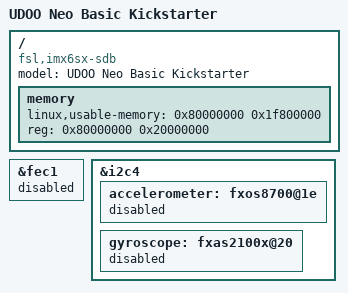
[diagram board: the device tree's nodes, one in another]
/*
 * Copyright (C) 2015 Jasbir Matharu
 * Author: Ettore Chimenti <ek5.chimenti@gmail.com>
 *
 * This program is free software; you can redistribute it and/or modify
 * it under the terms of the GNU General Public License version 2 as
 * published by the Free Software Foundation.
 */


/ {
	model = "UDOO Neo Basic Kickstarter";
	compatible = "fsl,imx6sx-sdb", "fsl,imx6sx";
	
	memory {
		linux,usable-memory = <0x80000000 0x1f800000>;
		reg = <0x80000000 0x20000000>;
	};
};

&fec1 {
	status = "disabled";
};

&i2c4 {
	accelerometer: fxos8700@1e {
		status = "disabled";
	};
	gyroscope: fxas2100x@20 {
		status = "disabled";
	};
};
